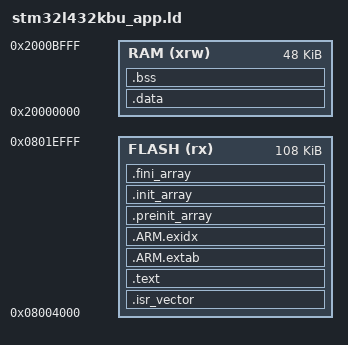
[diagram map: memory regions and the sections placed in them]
/* stm32l432kbu_app.ld - app at 0x08004000, last two pages reserved:
 * 0x0801F000 calibration, 0x0801F800 bootloader metadata
 */

MEMORY
{
  FLASH (rx)  : ORIGIN = 0x08004000, LENGTH = 0x1B000
  RAM   (xrw) : ORIGIN = 0x20000000, LENGTH = 48K
}

ENTRY(Reset_Handler)

_estack = ORIGIN(RAM) + LENGTH(RAM);

SECTIONS
{
  .isr_vector :
  {
    . = ALIGN(4);
    KEEP(*(.isr_vector))
  } > FLASH

  .text :
  {
    . = ALIGN(4);
    *(.text*)
    *(.rodata*)
    *(.glue_7)
    *(.glue_7t)
    *(.eh_frame)
    KEEP(*(.init))
    KEEP(*(.fini))
  } > FLASH

  .ARM.extab   : { *(.ARM.extab* .gnu.linkonce.armextab.*) } > FLASH
  .ARM.exidx   : { *(.ARM.exidx*) } > FLASH

  .preinit_array :
  {
    PROVIDE_HIDDEN (__preinit_array_start = .);
    KEEP (*(.preinit_array*))
    PROVIDE_HIDDEN (__preinit_array_end = .);
  } > FLASH

  .init_array :
  {
    PROVIDE_HIDDEN (__init_array_start = .);
    KEEP (*(SORT(.init_array.*)))
    KEEP (*(.init_array*))
    PROVIDE_HIDDEN (__init_array_end = .);
  } > FLASH

  .fini_array :
  {
    PROVIDE_HIDDEN (__fini_array_start = .);
    KEEP (*(SORT(.fini_array.*)))
    KEEP (*(.fini_array*))
    PROVIDE_HIDDEN (__fini_array_end = .);
  } > FLASH

  . = ALIGN(4);
  _etext = .;

  .data : AT(_etext)
  {
    . = ALIGN(4);
    _sdata = .;
    *(.data*)
    _edata = .;
  } > RAM
  _sidata = LOADADDR(.data);

  .bss :
  {
    . = ALIGN(4);
    _sbss = .;
    *(.bss*)
    *(COMMON)
    _ebss = .;
  } > RAM
}
